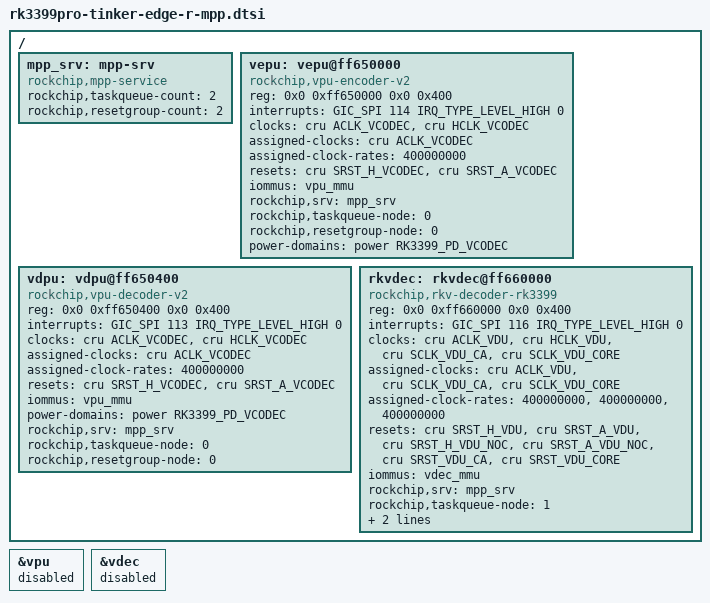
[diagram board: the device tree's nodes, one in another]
// SPDX-License-Identifier: (GPL-2.0+ OR MIT)
/*
 * Rockchip MPP video codec service nodes (from the Rockchip BSP 6.12
 * rk3399.dtsi). The VPU (ff650000) and the RKV decoder (ff660000) are driven
 * by mpp_service (/dev/mpp_service, userspace library `mpp`) instead of the
 * mainline V4L2 hantro/rkvdec drivers, which are disabled here.
 * Include after the board DTS.
 *
 * The assigned-clocks lines raise the codec clocks (the BSP driver did this in C and the
 * port stubs it; without them aclk_vcodec stays at 50 MHz and encoding runs at 4 fps).
 */

/ {
	mpp_srv: mpp-srv {
		compatible = "rockchip,mpp-service";
		rockchip,taskqueue-count = <2>;
		rockchip,resetgroup-count = <2>;
		status = "okay";
	};

	vepu: vepu@ff650000 {
		compatible = "rockchip,vpu-encoder-v2";
		reg = <0x0 0xff650000 0x0 0x400>;
		interrupts = <GIC_SPI 114 IRQ_TYPE_LEVEL_HIGH 0>;
		interrupt-names = "irq_enc";
		clocks = <&cru ACLK_VCODEC>, <&cru HCLK_VCODEC>;
		clock-names = "aclk_vcodec", "hclk_vcodec";
		assigned-clocks = <&cru ACLK_VCODEC>;
		assigned-clock-rates = <400000000>;
		resets = <&cru SRST_H_VCODEC>, <&cru SRST_A_VCODEC>;
		reset-names = "shared_video_h", "shared_video_a";
		iommus = <&vpu_mmu>;
		rockchip,srv = <&mpp_srv>;
		rockchip,taskqueue-node = <0>;
		rockchip,resetgroup-node = <0>;
		power-domains = <&power RK3399_PD_VCODEC>;
		status = "okay";
	};

	vdpu: vdpu@ff650400 {
		compatible = "rockchip,vpu-decoder-v2";
		reg = <0x0 0xff650400 0x0 0x400>;
		interrupts = <GIC_SPI 113 IRQ_TYPE_LEVEL_HIGH 0>;
		interrupt-names = "irq_dec";
		clocks = <&cru ACLK_VCODEC>, <&cru HCLK_VCODEC>;
		clock-names = "aclk_vcodec", "hclk_vcodec";
		assigned-clocks = <&cru ACLK_VCODEC>;
		assigned-clock-rates = <400000000>;
		resets = <&cru SRST_H_VCODEC>, <&cru SRST_A_VCODEC>;
		reset-names = "shared_video_h", "shared_video_a";
		iommus = <&vpu_mmu>;
		power-domains = <&power RK3399_PD_VCODEC>;
		rockchip,srv = <&mpp_srv>;
		rockchip,taskqueue-node = <0>;
		rockchip,resetgroup-node = <0>;
		status = "okay";
	};

	rkvdec: rkvdec@ff660000 {
		compatible = "rockchip,rkv-decoder-rk3399";
		reg = <0x0 0xff660000 0x0 0x400>;
		interrupts = <GIC_SPI 116 IRQ_TYPE_LEVEL_HIGH 0>;
		interrupt-names = "irq_dec";
		clocks = <&cru ACLK_VDU>, <&cru HCLK_VDU>,
			 <&cru SCLK_VDU_CA>, <&cru SCLK_VDU_CORE>;
		clock-names = "aclk_vcodec", "hclk_vcodec",
			      "clk_cabac", "clk_core";
		assigned-clocks = <&cru ACLK_VDU>, <&cru SCLK_VDU_CA>,
				  <&cru SCLK_VDU_CORE>;
		assigned-clock-rates = <400000000>, <400000000>, <400000000>;
		resets = <&cru SRST_H_VDU>, <&cru SRST_A_VDU>,
			 <&cru SRST_H_VDU_NOC>, <&cru SRST_A_VDU_NOC>,
			 <&cru SRST_VDU_CA>, <&cru SRST_VDU_CORE>;
		reset-names = "video_h", "video_a", "niu_h", "niu_a",
			      "video_cabac", "video_core";
		iommus = <&vdec_mmu>;
		rockchip,srv = <&mpp_srv>;
		rockchip,taskqueue-node = <1>;
		rockchip,resetgroup-node = <1>;
		power-domains = <&power RK3399_PD_VDU>;
		status = "okay";
	};
};

/* Mainline V4L2 drivers bind the same register ranges: turn them off. */
&vpu {
	status = "disabled";
};

&vdec {
	status = "disabled";
};
